VERSION "Practice_V1"

NS_ :

BS_:

BU_: Tester ECU

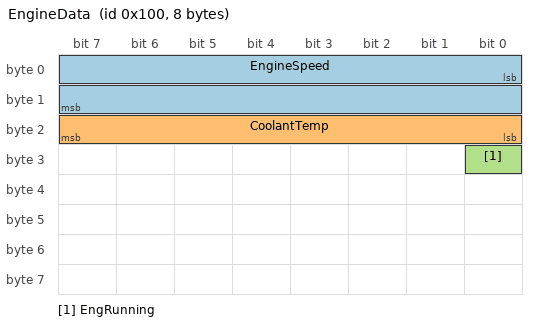
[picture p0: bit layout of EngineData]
BO_ 256 EngineData: 8 ECU
 SG_ EngineSpeed : 0|16@1+ (0.25,0) [0|16000] "rpm"  Tester
 SG_ CoolantTemp : 16|8@1+ (1,-40) [-40|215] "degC"  Tester
 SG_ EngRunning : 24|1@1+ (1,0) [0|1] ""  Tester

BO_ 512 VehicleStatus: 8 ECU
 SG_ VehicleSpeed : 0|16@1+ (0.01,0) [0|300] "km/h"  Tester
 SG_ Gear : 16|3@1+ (1,0) [0|7] ""  Tester

BO_ 768 MediaData: 8 ECU
 SG_ MediaStatus : 0|8@1+ (1,0) [0|1] ""  Tester

BO_ 1024 MediaControl: 8 Tester
 SG_ PlayPause : 0|8@1+ (1,0) [0|1] ""  ECU

BO_ 2015 DiagReq: 8 Tester
 SG_ DiagReqData : 0|64@1+ (1,0) [0|0] ""  ECU

BO_ 2024 DiagResp: 8 ECU
 SG_ DiagRespData : 0|64@1+ (1,0) [0|0] ""  Tester

BA_DEF_  "BusType" STRING ;
BA_DEF_DEF_  "BusType" "CAN";
VAL_ 768 MediaStatus 0 "Pause" 1 "Play" ;
VAL_ 1024 PlayPause 0 "Pause" 1 "Play" ;
